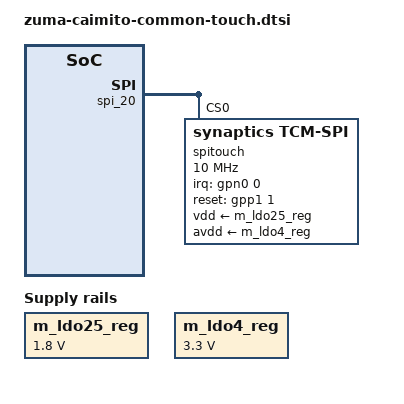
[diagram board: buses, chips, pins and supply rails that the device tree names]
// SPDX-License-Identifier: GPL-2.0-only
/*
 * Google caiman-komodo-tokay common touch device tree source
 *
 * Copyright 2023 Google, LLC.
 */

/* Touch is connected to spi_20, pins:
 *   CLK=GPB10[4], MOSI=GPB10[5], MISO=GPB10[6], CS=GPB10[7]
 * TS1_RESET_L = XAPC_USI11_RTSn_DI = GPP1[1] = <&gpp1 1 0>
 * TS1_INT_L = AOC_APM_TS1_INT_L_R1 / XAOC_GPIO0 = GPN0[0] = <&gpn0 0 0>
 *
 * DVDD = PP1800_L25M_TS1_DVDD = VLDO25M
 * AVDD = PP3300_L4M_TS1_AVDD  = VLDO4M
 */

#include <arm64/exynos/exynos-pinctrl.h>
#include <dt-bindings/regulator/samsung,s2mpg-regulator.h>

/ {
	fragment@touch_bus_negotiator {
		target-path = "/";
		__overlay__ {
			tbn: tbn {
				compatible = "touch_bus_negotiator";
				tbn,mode = <2>;
			};
		};
	};
};

&m_ldo25_reg {
	regulator-min-microvolt = <1800000>;
	regulator-max-microvolt = <1800000>;
};

&m_ldo4_reg {
	regulator-min-microvolt = <3300000>;
	regulator-max-microvolt = <3300000>;
};

/* GPIO_CUSTOM_ALIVE */
&pinctrl_1 {
	ts_irq: ts-irq {
		samsung,pins = "gpn0-0";
		samsung,pin-pud = <EXYNOS_PIN_PULL_NONE>;
		samsung,pin-drv = <ZUMA_PIN_DRV_X1>;
	};
};

&pinctrl_11 {
	ts_reset: ts-reset {
		samsung,pins = "gpp1-1";
		samsung,pin-pud = <EXYNOS_PIN_PULL_NONE>;
		samsung,pin-con-pdn = <EXYNOS_PIN_PDN_PREV>;
		samsung,pin-pud-pdn = <EXYNOS_PIN_PULL_NONE>;
	};
};

/* TODO: pinctrl for ts_spi_bus_active, ts_spi_cs_active,
 * ts_spi_bus_sleep, ts_spi_miso_sleep, ts_spi_cs_sleep
 */

&spi_20 {
	#address-cells = <1>;
	#size-cells = <0>;
	status = "okay";
	pinctrl-0 = <>; /* TODO: pinctrl */
	dma-mode;
	dmas = <&pdma1 18 &pdma1 19>;
	swap-mode = <1>;

	spitouch: touchscreen@0 {
		#address-cells = <1>;
		#size-cells = <1>;
		status = "ok";
		reg = <0>;
		compatible = "synaptics,tcm-spi";

		pinctrl-names = "ts_active", "ts_suspend";
		pinctrl-0 = <&ts_irq &ts_reset>; /* TODO: pinctrl */
		pinctrl-1 = <>;

		vdd-supply = <&m_ldo25_reg>;
		avdd-supply = <&m_ldo4_reg>;

		spi-max-frequency = <10000000>;

		synaptics,avdd-name = "avdd";
		synaptics,vdd-name = "vdd";
		synaptics,power-delay-ms = <200>;
		synaptics,irq-gpio = <&gpn0 0 0x2008>; /* IRQF_ONESHOT | IRQF_TRIGGER_LOW */
		synaptics,irq-on-state = <0>;
		synaptics,reset-gpio = <&gpp1 1 0>;
		synaptics,reset-on-state = <0>;
		synaptics,reset-active-ms = <2>;
		synaptics,reset-delay-ms = <50>;
		synaptics,spi-mode = <0>;
		synaptics,spi-byte-delay-us = <0>;
		synaptics,spi-block-delay-us = <0>;
/*
		synaptics,pixels-per-mm = <20>;
		synaptics,compression-threshold = <15>;
		synaptics,grip-delta-threshold = <50>;
		synaptics,grip-border-threshold = <50>;
		synaptics,panel_map = <&sdc_s6e3hc3_c10>,
				      <&sdc_s6e3hc4>,
				      <&boe_nt37290>;
		synaptics,firmware_names = "synaptics.img",
					   "synaptics.img",
					   "synaptics_b.img";
		synaptics,touch_offload_id = /bits/ 8 <'c' '1' '0' '0'>;
		synaptics,udfps-coords = <720 2360>;
		synaptics,dynamic-report-rate;
*/
		goog,coord-filter-enabled;
		goog,tbn-enabled;
		goog,manual-heatmap-from-irq;
		goog,v4l2-enabled;
		goog,offload-enabled;
		goog,lptw-suppress-coords-enabled;
		goog,reset-after-selftest;

		controller-data {
			samsung,spi-feedback-delay = <0>;
			samsung,spi-chip-select-mode = <0>;
			cs-clock-delay = <2>;
		};
	};
};
